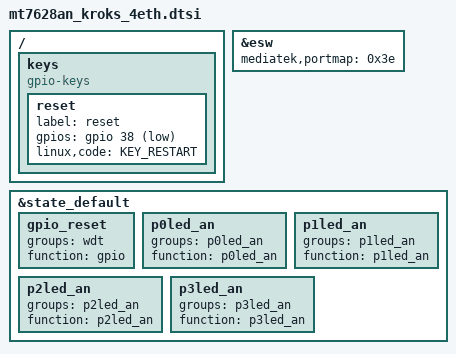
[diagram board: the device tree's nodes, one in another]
#include "mt7628an_kroks.dtsi"
#include "flash_kroks_16m.dtsi"

#include <dt-bindings/input/input.h>
#include <dt-bindings/gpio/gpio.h>

/ {
	keys {
		compatible = "gpio-keys";

		reset {
			label = "reset";
			gpios = <&gpio 38 GPIO_ACTIVE_LOW>;
			linux,code = <KEY_RESTART>;
		};
	};
};

&esw {
	mediatek,portmap = <0x3e>;
};

&state_default {
	gpio_reset {
		groups = "wdt";
		function = "gpio";
	};

	p0led_an {
		groups = "p0led_an";
		function = "p0led_an";
	};

	p1led_an {
		groups = "p1led_an";
		function = "p1led_an";
	};

	p2led_an {
		groups = "p2led_an";
		function = "p2led_an";
	};

	p3led_an {
		groups = "p3led_an";
		function = "p3led_an";
	};
};
